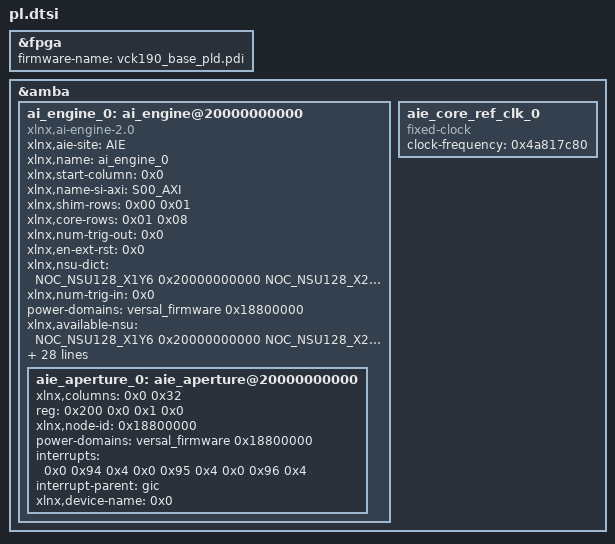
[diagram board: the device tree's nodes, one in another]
/dts-v1/;
/plugin/;

&fpga {
        firmware-name = "vck190_base_pld.pdi";
};

&amba {

        ai_engine_0: ai_engine@20000000000 {
                xlnx,aie-site = "AIE";
                xlnx,name = "ai_engine_0";
                xlnx,start-column = <0x0>;
                xlnx,name-si-axi = "S00_AXI";
                xlnx,shim-rows = /bits/ 8 <0x00 0x01>;
                xlnx,core-rows = /bits/ 8 <0x01 0x08>;
                xlnx,num-trig-out = <0x0>;
                xlnx,en-ext-rst = <0x0>;
                xlnx,nsu-dict = "NOC_NSU128_X1Y6 0x20000000000 NOC_NSU128_X2Y6 0x20001000000 NOC_NSU128_X3Y6 0x20001800000 NOC_NSU128_X4Y6 0x20002800000 NOC_NSU128_X5Y6 0x20003800000 NOC_NSU128_X6Y6 0x20005000000 NOC_NSU128_X7Y6 0x20008800000 NOC_NSU128_X8Y6 0x20009800000 NOC_NSU128_X9Y6 0x2000D800000 NOC_NSU128_X10Y6 0x2000E800000 NOC_NSU128_X11Y6 0x20012800000 NOC_NSU128_X12Y6 0x20013800000 NOC_NSU128_X13Y6 0x20017000000 NOC_NSU128_X14Y6 0x20017800000 NOC_NSU128_X15Y6 0x20018000000 NOC_NSU128_X16Y6 0x20018800000";
                xlnx,num-trig-in = <0x0>;
                power-domains = <&versal_firmware 0x18800000>;
                clock-names = "aclk0";
                xlnx,available-nsu = "NOC_NSU128_X1Y6 0x20000000000 NOC_NSU128_X2Y6 0x20001000000 NOC_NSU128_X3Y6 0x20001800000 NOC_NSU128_X4Y6 0x20002800000 NOC_NSU128_X5Y6 0x20003800000 NOC_NSU128_X6Y6 0x20005000000 NOC_NSU128_X7Y6 0x20008800000 NOC_NSU128_X8Y6 0x20009800000 NOC_NSU128_X9Y6 0x2000D800000 NOC_NSU128_X10Y6 0x2000E800000 NOC_NSU128_X11Y6 0x20012800000 NOC_NSU128_X12Y6 0x20013800000 NOC_NSU128_X13Y6 0x20017000000 NOC_NSU128_X14Y6 0x20017800000 NOC_NSU128_X15Y6 0x20018000000 NOC_NSU128_X16Y6 0x20018800000";
                xlnx,selected-nsu = <0x0>;
                xlnx,edk-iptype = "PERIPHERAL";
                xlnx,fast-dm-write;
                xlnx,name-si-axis = "S00_AXIS";
                xlnx,clk-names = "aclk0";
                xlnx,aie-core-ref-ctrl-freqmhz = <0x4e2>;
                xlnx,num-column = <0x1>;
                xlnx,name-mi-axi = "M00_AXI";
                xlnx,num-si-axis = <0x0>;
                #address-cells = <0x2>;
                xlnx,partition-enabled = <0x0>;
                xlnx,num-clks = <0x0>;
                ranges;
                xlnx,num-noc-axis-clks = <0x0>;
                clocks = <&aie_core_ref_clk_0>;
                reg = <0x200 0x0 0x1 0x0>;
                xlnx,fast-pm-write;
                xlnx,num-si-axi = <0x1>;
                #size-cells = <0x2>;
                xlnx,ip-name = "ai_engine";
                xlnx,mi-destid-pins;
                xlnx,mem-rows = /bits/ 8 <0x00 0x00>;
                xlnx,name-mi-axis = "M00_AXIS";
                xlnx,aie-gen = [01];
                xlnx,aie-max-freq = <0x4e2>;
                xlnx,en-addr-virtualization = <0x0>;
                xlnx,num-mi-axis = <0x0>;
                xlnx,aie-col-dict = "col00 0x20000000000 col01 0x20000800000 col02 0x20001000000 col03 0x20001800000 col04 0x20002000000 col05 0x20002800000 col06 0x20003000000 col07 0x20003800000 col08 0x20004000000 col09 0x20004800000 col10 0x20005000000 col11 0x20005800000 col12 0x20006000000 col13 0x20006800000 col14 0x20007000000 col15 0x20007800000 col16 0x20008000000 col17 0x20008800000 col18 0x20009000000 col19 0x20009800000 col20 0x2000A000000 col21 0x2000A800000 col22 0x2000B000000 col23 0x2000B800000 col24 0x2000C000000 col25 0x2000C800000 col26 0x2000D000000 col27 0x2000D800000 col28 0x2000E000000 col29 0x2000E800000 col30 0x2000F000000 col31 0x2000F800000 col32 0x20010000000 col33 0x20010800000 col34 0x20011000000 col35 0x20011800000 col36 0x20012000000 col37 0x20012800000 col38 0x20013000000 col39 0x20013800000 col40 0x20014000000 col41 0x20014800000 col42 0x20015000000 col43 0x20015800000 col44 0x20016000000 col45 0x20016800000 col46 0x20017000000 col47 0x20017800000 col48 0x20018000000 col49 0x20018800000";
                xlnx,aie-ref-clk-freqmhz = <0x1fc9f08>;
                compatible = "xlnx,ai-engine-2.0", "xlnx,ai-engine-v2.0";
                xlnx,num-mi-axi = <0x0>;

                aie_aperture_0: aie_aperture@20000000000 {
                        xlnx,columns = <0x0 0x32>;
                        reg = <0x200 0x0 0x1 0x0>;
                        interrupt-names = "interrupt1", "interrupt2", "interrupt3";
                        #size-cells = <0x2>;
                        xlnx,node-id = <0x18800000>;
                        power-domains = <&versal_firmware 0x18800000>;
                        #address-cells = <0x2>;
                        interrupts = <0x0 0x94 0x4 0x0 0x95 0x4 0x0 0x96 0x4>;
                        interrupt-parent = <&gic>;
                        xlnx,device-name = <0x0>;
                };
        };

        aie_core_ref_clk_0: aie_core_ref_clk_0 {
                #clock-cells = <0x0>;
                clock-frequency = <0x4a817c80>;
                compatible = "fixed-clock";
        };
};

